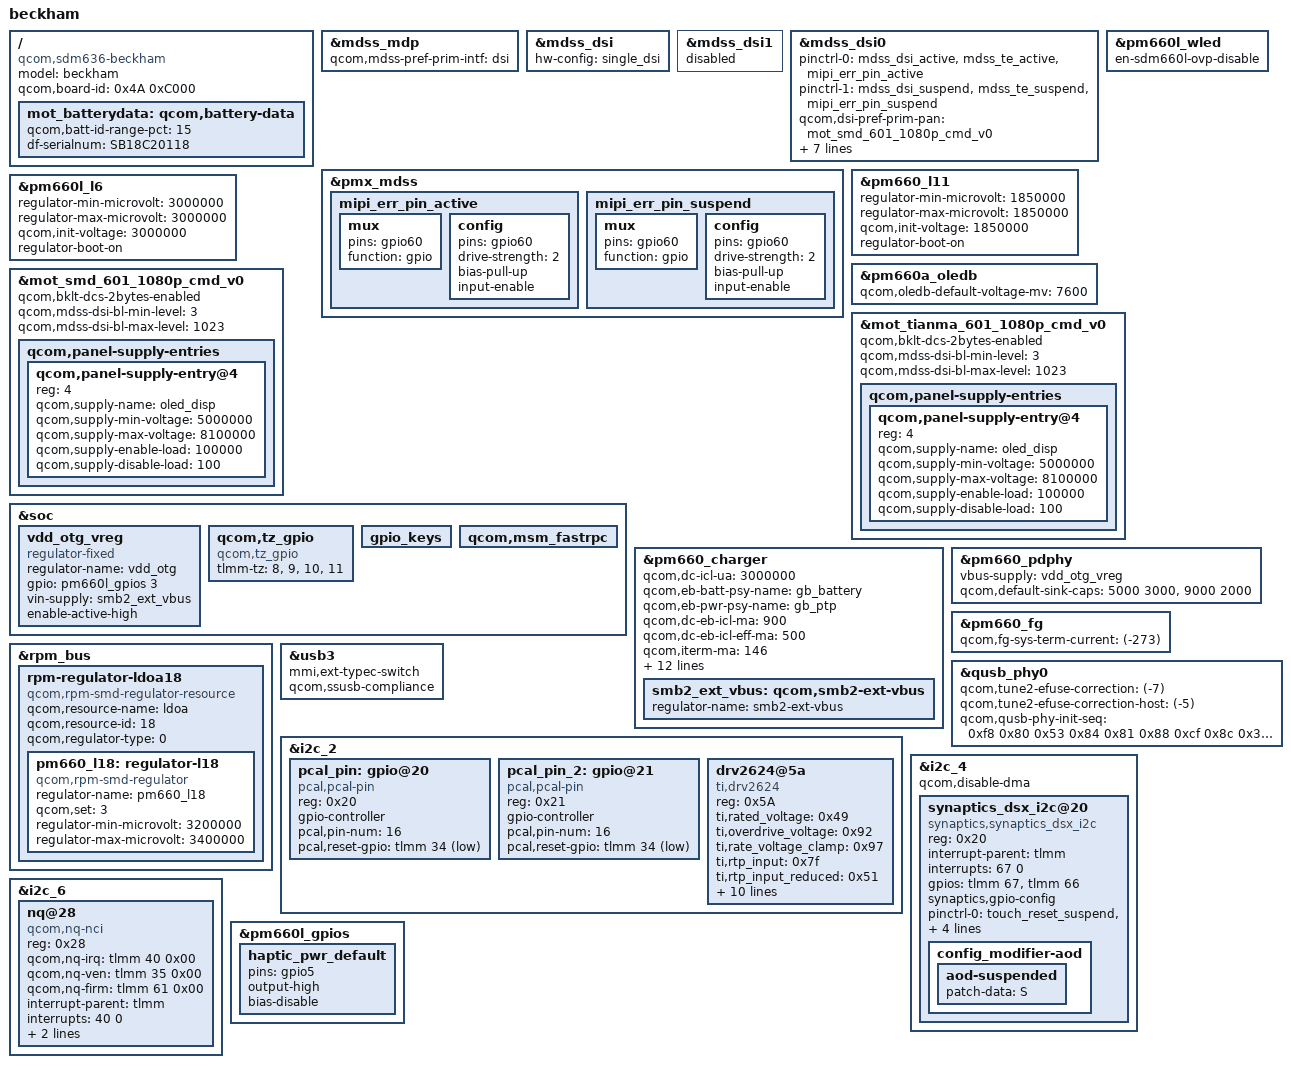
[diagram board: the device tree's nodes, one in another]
/dts-v1/;

// Include required dtsi
#include "../../sdm636.dtsi"
#include "../../msm-pm660a.dtsi"
#include "../moto-common.dtsi"
#include "pinctrl.dtsi"
#include "audio.dtsi"
#include "camera.dtsi"
#include "dsi-panel-mot-smd-601-1080p-cmd.dtsi"
#include "dsi-panel-mot-tianma-601-1080p-cmd.dtsi"

/ {
	model = "beckham";
	compatible = "qcom,sdm636-beckham", "qcom,sdm636-moto",
                    "qcom,sdm636";
	qcom,board-id = <0x4A 0xC000>;

	// Battery
	mot_batterydata: qcom,battery-data {
		qcom,batt-id-range-pct = <15>;
		df-serialnum = "SB18C20118";
		#include "batterydata-js40-scud-pm660.dtsi"
		#include "batterydata-js40-swd-pm660.dtsi"
	};
};

// TEMP single display until mods are up
&mdss_mdp {
	qcom,mdss-pref-prim-intf = "dsi";
};

&mdss_dsi {
	hw-config = "single_dsi";
};

&mdss_dsi1 {
	status = "disabled";
};

// Display configuration
&mdss_dsi0 {
	pinctrl-names = "mdss_default", "mdss_sleep";
	pinctrl-0 = <&mdss_dsi_active &mdss_te_active &mipi_err_pin_active>;
	pinctrl-1 = <&mdss_dsi_suspend &mdss_te_suspend &mipi_err_pin_suspend>;

	qcom,dsi-pref-prim-pan = <&mot_smd_601_1080p_cmd_v0>;
	vci_disp-supply = <&pm660l_l6>;
	vio_disp-supply = <&pm660_l11>;
	elvdd_disp-supply = <&lab_regulator>;
	elvss_disp-supply = <&ibb_regulator>;
	oled_disp-supply = <&pm660a_oledb>;
	qcom,platform-reset-gpio = <&tlmm 53 0>;
	qcom,platform-te-gpio = <&tlmm 59 0>;
};

&pm660l_wled {
	en-sdm660l-ovp-disable;
};

// Display pinctrl
&pmx_mdss {
	mipi_err_pin_active: mipi_err_pin_active {
		mux {
			pins = "gpio60";
			function = "gpio";
		};

		config {
			pins = "gpio60";
			drive-strength = <2>; /* 2 mA */
			bias-pull-up; /* pull up */
			input-enable;
		};
	};

	mipi_err_pin_suspend: mipi_err_pin_suspend {
		mux {
			pins = "gpio60";
			function = "gpio";
		};

		config {
			pins = "gpio60";
			drive-strength = <2>; /* 2 mA */
			bias-pull-up; /* pull up */
			input-enable;
		};
	};
};

&pm660_l11 {
	regulator-min-microvolt = <1850000>;
	regulator-max-microvolt = <1850000>;
	qcom,init-voltage = <1850000>;
	regulator-boot-on;
};

&pm660l_l6 {
	regulator-min-microvolt = <3000000>;
	regulator-max-microvolt = <3000000>;
	qcom,init-voltage = <3000000>;
	regulator-boot-on;
};

&pm660a_oledb {
	qcom,oledb-default-voltage-mv = <7600>;
};

&mot_smd_601_1080p_cmd_v0 {
	qcom,bklt-dcs-2bytes-enabled;
	qcom,mdss-dsi-bl-min-level = <3>;
	qcom,mdss-dsi-bl-max-level = <1023>;

	qcom,panel-supply-entries {
			qcom,panel-supply-entry@4 {
				reg = <4>;
				qcom,supply-name = "oled_disp";
				qcom,supply-min-voltage = <5000000>;
				qcom,supply-max-voltage = <8100000>;
				qcom,supply-enable-load = <100000>;
				qcom,supply-disable-load = <100>;
			};
	};
};

&mot_tianma_601_1080p_cmd_v0 {
	qcom,bklt-dcs-2bytes-enabled;
	qcom,mdss-dsi-bl-min-level = <3>;
	qcom,mdss-dsi-bl-max-level = <1023>;

	qcom,panel-supply-entries {
			qcom,panel-supply-entry@4 {
				reg = <4>;
				qcom,supply-name = "oled_disp";
				qcom,supply-min-voltage = <5000000>;
				qcom,supply-max-voltage = <8100000>;
				qcom,supply-enable-load = <100000>;
				qcom,supply-disable-load = <100>;
			};
	};
};

&soc {
	// USB
	vdd_otg_vreg: vdd_otg_vreg {
		compatible = "regulator-fixed";
		regulator-name = "vdd_otg";
		gpio = <&pm660l_gpios 3 0>;
		vin-supply = <&smb2_ext_vbus>;
		enable-active-high;
	};

	// Protected GPIOs
	qcom,tz_gpio {
		compatible = "qcom,tz_gpio";
		tlmm-tz = <8>,
			<9>,
			<10>,
			<11>;
	};

	// Remove GPIO pinctrl
	gpio_keys {
		/delete-property/ pinctrl-names;
		/delete-property/ pinctrl-0;
		/delete-property/ pinctrl-1;
	};

	// SDM636 does not have a SEE, sensors are placed in adsp instead
	qcom,msm_fastrpc {
		/delete-property/ qcom,fastrpc-adsp-sensors-pdr;
	};
};

// Charger/USB
&pm660_charger {
	qcom,dc-icl-ua = <3000000>;
	qcom,eb-batt-psy-name = "gb_battery";
	qcom,eb-pwr-psy-name = "gb_ptp";
	qcom,dc-eb-icl-ma = <900>;
	qcom,dc-eb-icl-eff-ma = <500>;
	qcom,iterm-ma = <146>;
	qcom,dc-thermal-mitigation = <3000>,
				     <1500>,
				     <900>,
				     <600>,
				     <300>;
	qcom,mmi-temp-zones = <0 4200 582 0>,
				<10 4200 1455 582>,
				<15 0 1455 1455>,
				<45 4200 3000 2000>,
				<60 4200 1455 0>;
	qcom,vfloat-comp-uv = <20000>;
	qcom,typec-debounce;
	qcom,external-vconn;
	qcom,external-vbus;
	qcom,use-single-path-usbin-switch;
	gpios = <&pm660l_gpios 8 0x0>; /* GPIOF_OUT_INIT_LOW */
	gpio-names = "eb_vbus_en";
	smb2_ext_vbus: qcom,smb2-ext-vbus {
		regulator-name = "smb2-ext-vbus";
	};
};

&pm660_pdphy {
	vbus-supply = <&vdd_otg_vreg>;
	qcom,default-sink-caps = <5000 3000>, /* 5V @ 3A */
				<9000 2000>; /* 9V @ 2A */
};

&pm660_fg {
	qcom,fg-sys-term-current = <(-273)>;
};

&rpm_bus {
	rpm-regulator-ldoa18 {
		compatible = "qcom,rpm-smd-regulator-resource";
		qcom,resource-name = "ldoa";
		qcom,resource-id = <18>;
		qcom,regulator-type = <0>;
		status = "okay";
		pm660_l18: regulator-l18 {
			compatible = "qcom,rpm-smd-regulator";
			regulator-name = "pm660_l18";
			qcom,set = <3>;
			regulator-min-microvolt = <3200000>;
			regulator-max-microvolt = <3400000>;
			status = "okay";
		};
	};
};

&usb3 {
	mmi,ext-typec-switch;
	qcom,ssusb-compliance;
};

&qusb_phy0 {
	qcom,tune2-efuse-correction = <(-7)>;
	qcom,tune2-efuse-correction-host = <(-5)>;
	qcom,qusb-phy-init-seq = <0xf8 0x80
				0x53 0x84
				0x81 0x88
				0xcf 0x8c
				0x30 0x08
				0x79 0x0c
				0x21 0x10
				0x14 0x9c
				0x9f 0x1c
				0x00 0x18>;
};

// Peripherials
&i2c_2 {
	status = "ok";

	pcal_pin:gpio@20 {
		compatible = "pcal,pcal-pin";
		status = "ok";
		reg = <0x20>;
		gpio-controller;
		#gpio-cells = <2>;
		#address-cells = <1>;
		pcal,pin-num = <16>;
		pcal,reset-gpio = <&tlmm 34 1>;
	};

	pcal_pin_2:gpio@21 {
		compatible = "pcal,pcal-pin";
		status = "ok";
		reg = <0x21>;
		gpio-controller;
		#gpio-cells = <2>;
		#address-cells = <1>;
		pcal,pin-num = <16>;
		pcal,reset-gpio = <&tlmm 34 1>;
	};

	drv2624@5a {
		status = "ok";
		compatible = "ti,drv2624";
		reg = <0x5A>;
		/* voltage = *_voltage x 22 mV */
		/* 1.8V for now */
		ti,rated_voltage = /bits/ 8 <0x49>;
		ti,overdrive_voltage = /bits/ 8 <0x92>;
		ti,rate_voltage_clamp = /bits/ 8 <0x97>;
		ti,rtp_input = /bits/ 8 <0x7f>;
		ti,rtp_input_reduced = /bits/ 8 <0x51>;
		/* LRA period = lra_freq x 24.39 us */
		/* 205 Hz for now */
		ti,lra_freq = /bits/ 8 <0xCD>;
		ti,lra_drive;
		ti,auto_cal;
		ti,auto_cal_time = /bits/ 8 <0x01>;
		/* sample time 300us  */
		ti,sample_time = /bits/ 8 <0x1c>;
		ti,drive_time = /bits/ 8 <0x13>;
		ti,nrst-gpio = <&pcal_pin 10 0>;
		ti,nvctrl-gpio = <&tlmm 57 0>;
		ti,npwr-gpio = <&pm660l_gpios 5 0>;
		pinctrl-names = "default";
		pinctrl-0 = <&haptic_pwr_default>;
	};
};

&i2c_4 {
	status = "okay";
	qcom,disable-dma;
	synaptics_dsx_i2c@20 {
		compatible = "synaptics,synaptics_dsx_i2c";
		reg = <0x20>;
		interrupt-parent = <&tlmm>;
		interrupts = <67 0>;
		gpios = <&tlmm 67 0>, /* IRQ */
			<&tlmm 66 0>; /* RESET */
		synaptics,gpio-config;
		pinctrl-names = "default", "active";
		pinctrl-0 = <&touch_reset_suspend &touch_int_suspend>;
		pinctrl-1 = <&touch_reset_active &touch_int_active>;
		config_modifier-names = "aod";
		config_modifier-aod {
			aod-suspended {
				/* Power->sleep; */
				patch-data = "S";
			};
		};
	};
};

&i2c_6 {
	status = "okay";
	nq@28 {
		compatible = "qcom,nq-nci";
		reg = <0x28>;
		qcom,nq-irq = <&tlmm 40 0x00>;
		qcom,nq-ven = <&tlmm 35 0x00>;
		qcom,nq-firm = <&tlmm 61 0x00>;
		interrupt-parent = <&tlmm>;
		interrupts = <40 0>;
		interrupt-names = "nfc_irq";
		pinctrl-names = "nfc_active", "nfc_suspend";
		pinctrl-0 = <&nfc_int_active &nfc_enable_active>;
		pinctrl-1 = <&nfc_int_suspend &nfc_enable_suspend>;
	};
};

&pm660l_gpios {
	haptic_pwr_default: haptic_pwr_default {
		pins = "gpio5";
		output-high;
		bias-disable;
	};
};
